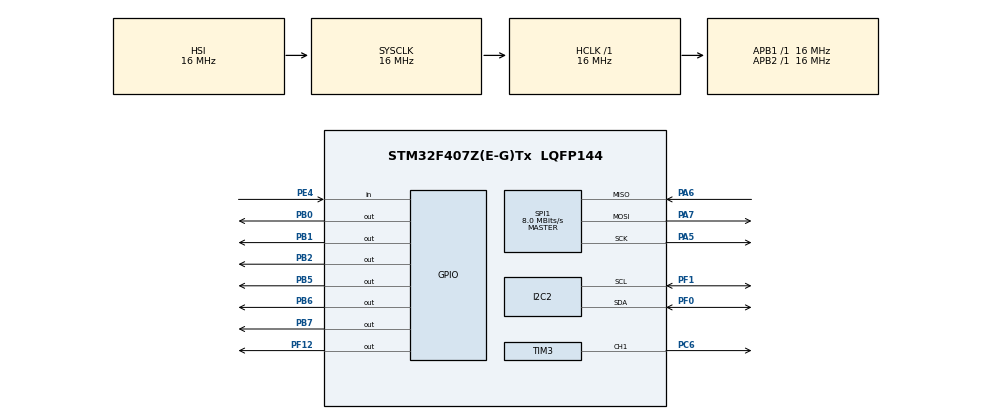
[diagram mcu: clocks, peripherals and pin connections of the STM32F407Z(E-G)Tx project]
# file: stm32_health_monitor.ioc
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Mcu.Family=STM32F4
Mcu.Name=STM32F407Z(E-G)Tx
Mcu.Package=LQFP144
NVIC.I2C2_EV_IRQn=true\:0\:0\:false\:false\:true\:true\:true\:true
NVIC.PriorityGroup=NVIC_PRIORITYGROUP_4
PA13.Mode=Serial_Wire
PA13.Signal=SYS_JTMS-SWDIO
PA14.Mode=Serial_Wire
PA14.Signal=SYS_JTCK-SWCLK
PA5.Mode=Full_Duplex_Master
PA5.Signal=SPI1_SCK
PA6.Mode=Full_Duplex_Master
PA6.Signal=SPI1_MISO
PA7.Mode=Full_Duplex_Master
PA7.Signal=SPI1_MOSI
PB0.Signal=GPIO_Output
PB1.Signal=GPIO_Output
PB2.Signal=GPIO_Output
PB5.Signal=GPIO_Output
PB6.Signal=GPIO_Output
PB7.Signal=GPIO_Output
PC6.Signal=S_TIM3_CH1
PE4.GPIO_PuPd=GPIO_PULLDOWN
PE4.Signal=GPIO_Input
PF0.Mode=I2C
PF0.Signal=I2C2_SDA
PF1.Mode=I2C
PF1.Signal=I2C2_SCL
PF12.Signal=GPIO_Output
ProjectManager.HeapSize=0x200
ProjectManager.StackSize=0x400
ProjectManager.TargetToolchain=MDK-ARM V5.32
RCC.AHBFreq_Value=16000000
RCC.APB1Freq_Value=16000000
RCC.APB2Freq_Value=16000000
RCC.CortexFreq_Value=16000000
RCC.HSE_VALUE=25000000
RCC.HSI_VALUE=16000000
RCC.LSE_VALUE=32768
RCC.SYSCLKFreq_VALUE=16000000
RCC.VCOOutputFreq_Value=192000000
SH.S_TIM3_CH1.0=TIM3_CH1,PWM Generation1 CH1
SPI1.CalculateBaudRate=8.0 MBits/s
SPI1.Direction=SPI_DIRECTION_2LINES
SPI1.Mode=SPI_MODE_MASTER
SPI1.VirtualType=VM_MASTER
TIM3.AutoReloadPreload=TIM_AUTORELOAD_PRELOAD_ENABLE
TIM3.Channel-PWM\ Generation1\ CH1=TIM_CHANNEL_1
TIM3.Period=20000-1
TIM3.Prescaler=15
TIM3.Pulse-PWM\ Generation1\ CH1=500
TIM3.TIM_MasterOutputTrigger=TIM_TRGO_UPDATE
TIM6.Period=0xFFFF
TIM6.Prescaler=83
VP_TIM3_VS_ClockSourceINT.Mode=Internal
VP_TIM6_VS_ClockSourceINT.Mode=Enable_Timer
board=custom

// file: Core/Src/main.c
/* USER CODE BEGIN Header */
/**
  ******************************************************************************
  * @file           : main.c
  * @brief          : Main program body
  ******************************************************************************
  * @attention
  *
  * Copyright (c) 2025 STMicroelectronics.
  * All rights reserved.
  *
  * This software is licensed under terms that can be found in the LICENSE file
  * in the root directory of this software component.
  * If no LICENSE file comes with this software, it is provided AS-IS.
  *
  ******************************************************************************
  */
/* USER CODE END Header */
#include "main.h"
#include "i2c.h"
#include "spi.h"
#include "tim.h"
#include "gpio.h"

/* USER CODE BEGIN Includes */
#include "bsp_system.h"
/* USER CODE END Includes */

void SystemClock_Config(void);

int main(void)
{

  /* MCU Configuration--------------------------------------------------------*/

  /* Reset of all peripherals, Initializes the Flash interface and the Systick. */
  HAL_Init();

  /* USER CODE BEGIN Init */
    scheduler_init();
	OLED_Init();
    MLX90614_Init();
    MAX30102_Init();
    SG90_Init();
	DS1302_Init();
	DS1302_SetTime(25, 7, 1, 23, 59, 54);
    BEEPER_Init();
    Delay_Init(&Delay_sg90);
  /* USER CODE END Init */

  /* Configure the system clock */
  SystemClock_Config();

  /* Initialize all configured peripherals */
  MX_GPIO_Init();
  MX_I2C2_Init();
  MX_SPI1_Init();
  MX_TIM3_Init();
  MX_TIM6_Init();

  /* Infinite loop */
  /* USER CODE BEGIN WHILE */
  while (1)
  {
      scheduler_run();
    /* USER CODE END WHILE */

  }
}

void SystemClock_Config(void)
{
  RCC_OscInitTypeDef RCC_OscInitStruct = {0};
  RCC_ClkInitTypeDef RCC_ClkInitStruct = {0};

  /** Configure the main internal regulator output voltage
  */
  __HAL_RCC_PWR_CLK_ENABLE();
  __HAL_PWR_VOLTAGESCALING_CONFIG(PWR_REGULATOR_VOLTAGE_SCALE1);

  /** Initializes the RCC Oscillators according to the specified parameters
  * in the RCC_OscInitTypeDef structure.
  */
  RCC_OscInitStruct.OscillatorType = RCC_OSCILLATORTYPE_HSI;
  RCC_OscInitStruct.HSIState = RCC_HSI_ON;
  RCC_OscInitStruct.HSICalibrationValue = RCC_HSICALIBRATION_DEFAULT;
  RCC_OscInitStruct.PLL.PLLState = RCC_PLL_NONE;
  if (HAL_RCC_OscConfig(&RCC_OscInitStruct) != HAL_OK)
  {
    Error_Handler();
  }

  /** Initializes the CPU, AHB and APB buses clocks
  */
  RCC_ClkInitStruct.ClockType = RCC_CLOCKTYPE_HCLK|RCC_CLOCKTYPE_SYSCLK
                              |RCC_CLOCKTYPE_PCLK1|RCC_CLOCKTYPE_PCLK2;
  RCC_ClkInitStruct.SYSCLKSource = RCC_SYSCLKSOURCE_HSI;
  RCC_ClkInitStruct.AHBCLKDivider = RCC_SYSCLK_DIV1;
  RCC_ClkInitStruct.APB1CLKDivider = RCC_HCLK_DIV1;
  RCC_ClkInitStruct.APB2CLKDivider = RCC_HCLK_DIV1;

  if (HAL_RCC_ClockConfig(&RCC_ClkInitStruct, FLASH_LATENCY_0) != HAL_OK)
  {
    Error_Handler();
  }
}

void Error_Handler(void)
{
  __disable_irq();
  while (1)
  {
  }
}
